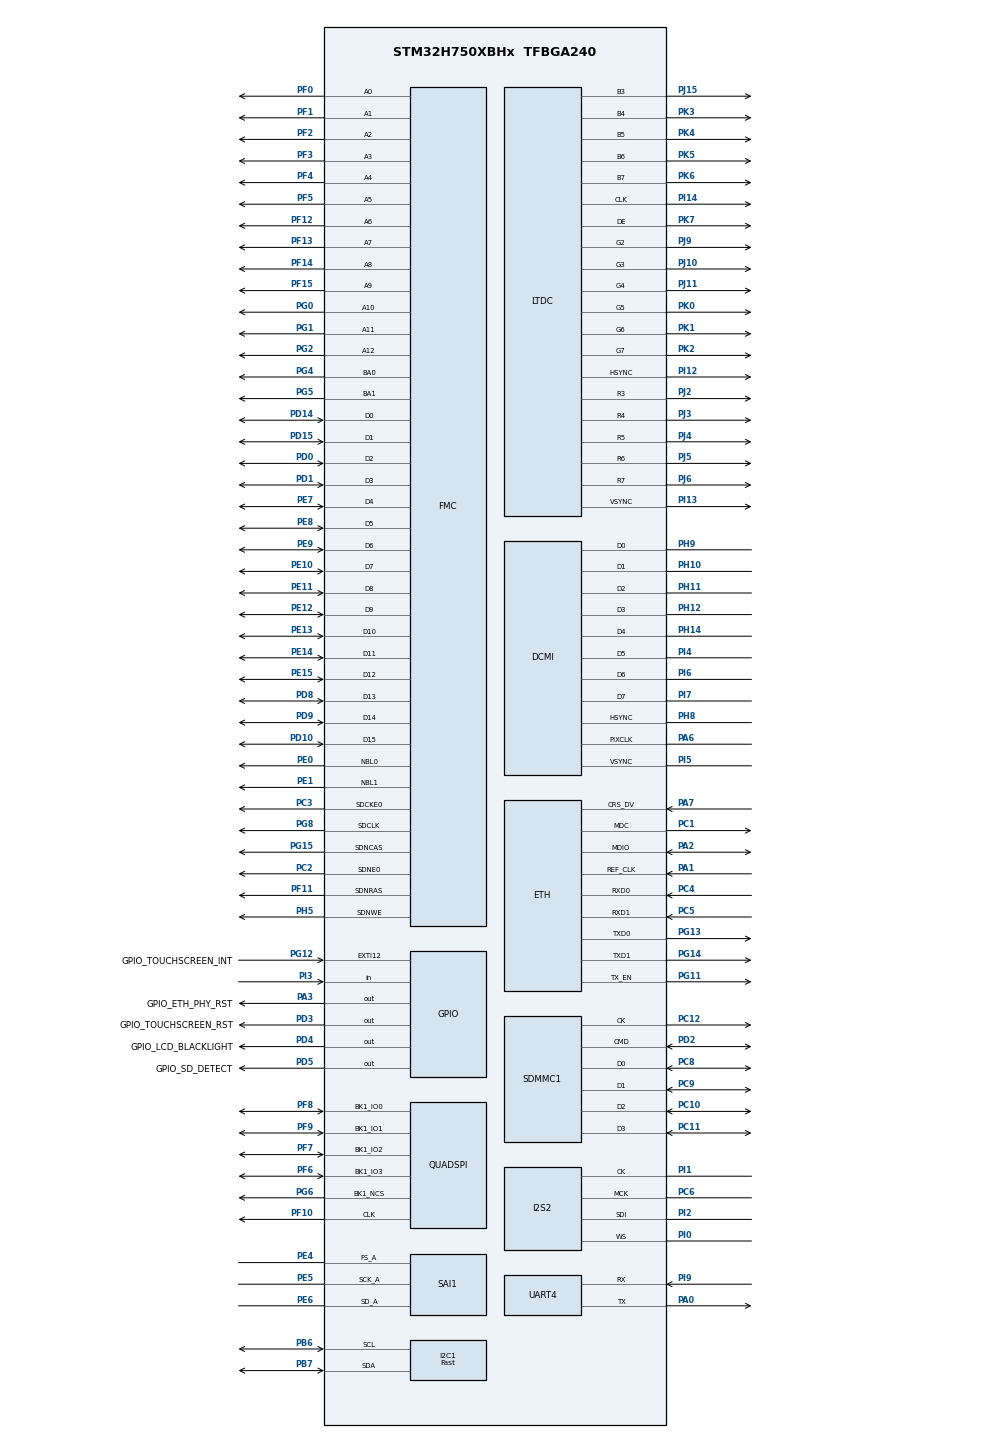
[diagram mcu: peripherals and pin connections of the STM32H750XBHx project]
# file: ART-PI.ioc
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CORTEX_M7.CPU_DCache=Enabled
CORTEX_M7.CPU_ICache=Enabled
CORTEX_M7.Enable_S-Cortex_Memory_Protection_Unit_Region1_Settings_S=__NULL
CORTEX_M7.default_mode_Activation=0
DCMI.JPEGMode=DCMI_JPEG_DISABLE
DMA2D.ColorMode=DMA2D_OUTPUT_RGB565
Dma.I2C1_RX.1.Direction=DMA_PERIPH_TO_MEMORY
Dma.I2C1_RX.1.EventEnable=DISABLE
Dma.I2C1_RX.1.FIFOMode=DMA_FIFOMODE_ENABLE
Dma.I2C1_RX.1.FIFOThreshold=DMA_FIFO_THRESHOLD_FULL
Dma.I2C1_RX.1.Instance=DMA1_Stream1
Dma.I2C1_RX.1.MemBurst=DMA_MBURST_SINGLE
Dma.I2C1_RX.1.MemDataAlignment=DMA_MDATAALIGN_BYTE
Dma.I2C1_RX.1.MemInc=DMA_MINC_ENABLE
Dma.I2C1_RX.1.Mode=DMA_NORMAL
Dma.I2C1_RX.1.PeriphBurst=DMA_PBURST_SINGLE
Dma.I2C1_RX.1.PeriphDataAlignment=DMA_PDATAALIGN_BYTE
Dma.I2C1_RX.1.PeriphInc=DMA_PINC_DISABLE
Dma.I2C1_RX.1.Polarity=HAL_DMAMUX_REQ_GEN_RISING
Dma.I2C1_RX.1.Priority=DMA_PRIORITY_LOW
Dma.I2C1_RX.1.RequestNumber=1
Dma.I2C1_RX.1.SignalID=NONE
Dma.I2C1_RX.1.SyncEnable=DISABLE
Dma.I2C1_RX.1.SyncPolarity=HAL_DMAMUX_SYNC_NO_EVENT
Dma.I2C1_RX.1.SyncRequestNumber=1
Dma.I2C1_RX.1.SyncSignalID=NONE
Dma.I2C1_TX.0.Direction=DMA_MEMORY_TO_PERIPH
Dma.I2C1_TX.0.EventEnable=DISABLE
Dma.I2C1_TX.0.FIFOMode=DMA_FIFOMODE_ENABLE
Dma.I2C1_TX.0.FIFOThreshold=DMA_FIFO_THRESHOLD_FULL
Dma.I2C1_TX.0.Instance=DMA1_Stream0
Dma.I2C1_TX.0.MemBurst=DMA_MBURST_SINGLE
Dma.I2C1_TX.0.MemDataAlignment=DMA_MDATAALIGN_BYTE
Dma.I2C1_TX.0.MemInc=DMA_MINC_ENABLE
Dma.I2C1_TX.0.Mode=DMA_NORMAL
Dma.I2C1_TX.0.PeriphBurst=DMA_PBURST_SINGLE
Dma.I2C1_TX.0.PeriphDataAlignment=DMA_PDATAALIGN_BYTE
Dma.I2C1_TX.0.PeriphInc=DMA_PINC_DISABLE
Dma.I2C1_TX.0.Polarity=HAL_DMAMUX_REQ_GEN_RISING
Dma.I2C1_TX.0.Priority=DMA_PRIORITY_LOW
Dma.I2C1_TX.0.RequestNumber=1
Dma.I2C1_TX.0.SignalID=NONE
Dma.I2C1_TX.0.SyncEnable=DISABLE
Dma.I2C1_TX.0.SyncPolarity=HAL_DMAMUX_SYNC_NO_EVENT
Dma.I2C1_TX.0.SyncRequestNumber=1
Dma.I2C1_TX.0.SyncSignalID=NONE
Dma.Request0=I2C1_TX
Dma.Request1=I2C1_RX
Dma.Request2=SAI1_A
Dma.Request3=SPI2_RX
Dma.SAI1_A.2.Direction=DMA_MEMORY_TO_PERIPH
Dma.SAI1_A.2.EventEnable=DISABLE
Dma.SAI1_A.2.FIFOMode=DMA_FIFOMODE_ENABLE
Dma.SAI1_A.2.FIFOThreshold=DMA_FIFO_THRESHOLD_HALFFULL
Dma.SAI1_A.2.Instance=DMA1_Stream2
Dma.SAI1_A.2.MemBurst=DMA_MBURST_SINGLE
Dma.SAI1_A.2.MemDataAlignment=DMA_MDATAALIGN_HALFWORD
Dma.SAI1_A.2.MemInc=DMA_MINC_ENABLE
Dma.SAI1_A.2.Mode=DMA_CIRCULAR
Dma.SAI1_A.2.PeriphBurst=DMA_PBURST_SINGLE
Dma.SAI1_A.2.PeriphDataAlignment=DMA_PDATAALIGN_HALFWORD
Dma.SAI1_A.2.PeriphInc=DMA_PINC_DISABLE
Dma.SAI1_A.2.Polarity=HAL_DMAMUX_REQ_GEN_RISING
Dma.SAI1_A.2.Priority=DMA_PRIORITY_LOW
Dma.SAI1_A.2.RequestNumber=1
Dma.SAI1_A.2.SignalID=NONE
Dma.SAI1_A.2.SyncEnable=DISABLE
Dma.SAI1_A.2.SyncPolarity=HAL_DMAMUX_SYNC_NO_EVENT
Dma.SAI1_A.2.SyncRequestNumber=1
Dma.SAI1_A.2.SyncSignalID=NONE
Dma.SPI2_RX.3.Direction=DMA_PERIPH_TO_MEMORY
Dma.SPI2_RX.3.EventEnable=DISABLE
Dma.SPI2_RX.3.FIFOMode=DMA_FIFOMODE_ENABLE
Dma.SPI2_RX.3.FIFOThreshold=DMA_FIFO_THRESHOLD_HALFFULL
Dma.SPI2_RX.3.Instance=DMA1_Stream3
Dma.SPI2_RX.3.MemBurst=DMA_MBURST_SINGLE
Dma.SPI2_RX.3.MemDataAlignment=DMA_MDATAALIGN_WORD
Dma.SPI2_RX.3.MemInc=DMA_MINC_ENABLE
Dma.SPI2_RX.3.Mode=DMA_CIRCULAR
Dma.SPI2_RX.3.PeriphBurst=DMA_PBURST_SINGLE
Dma.SPI2_RX.3.PeriphDataAlignment=DMA_PDATAALIGN_WORD
Dma.SPI2_RX.3.PeriphInc=DMA_PINC_DISABLE
Dma.SPI2_RX.3.Polarity=HAL_DMAMUX_REQ_GEN_RISING
Dma.SPI2_RX.3.Priority=DMA_PRIORITY_LOW
Dma.SPI2_RX.3.RequestNumber=1
Dma.SPI2_RX.3.SignalID=NONE
Dma.SPI2_RX.3.SyncEnable=DISABLE
Dma.SPI2_RX.3.SyncPolarity=HAL_DMAMUX_SYNC_NO_EVENT
Dma.SPI2_RX.3.SyncRequestNumber=1
Dma.SPI2_RX.3.SyncSignalID=NONE
ETH.MediaInterface=HAL_ETH_RMII_MODE
FATFS._CODE_PAGE=1
FATFS._FS_LOCK=16
FATFS._LFN_UNICODE=0
FATFS._STRF_ENCODE=0
FATFS._USE_CHMOD=1
FATFS._USE_LFN=0
FATFS._USE_MUTEX=1
FMC.BankMapConfig=FMC_SWAPBMAP_DISABLE
FMC.CASLatency1=FMC_SDRAM_CAS_LATENCY_2
FMC.ColumnBitsNumber1=FMC_SDRAM_COLUMN_BITS_NUM_9
FMC.ExitSelfRefreshDelay1=8
FMC.LoadToActiveDelay1=2
FMC.RCDDelay1=2
FMC.RPDelay1=2
FMC.RPDelay2=2
FMC.ReadBurst1=FMC_SDRAM_RBURST_ENABLE
FMC.ReadBurst2=FMC_SDRAM_RBURST_ENABLE
FMC.RowCycleDelay1=6
FMC.RowCycleDelay2=6
FMC.SDClockPeriod1=FMC_SDRAM_CLOCK_PERIOD_2
FMC.SDClockPeriod2=FMC_SDRAM_CLOCK_PERIOD_2
FMC.SelfRefreshTime1=6
FMC.WriteRecoveryTime1=6
FREERTOS.Tasks01=defaultTask,24,128,StartDefaultTask,Default,NULL,Dynamic,NULL,NULL
FREERTOS.configCHECK_FOR_STACK_OVERFLOW=1
FREERTOS.configENABLE_FPU=1
FREERTOS.configTIMER_TASK_STACK_DEPTH=512
FREERTOS.configTOTAL_HEAP_SIZE=102400
FREERTOS.configUSE_DAEMON_TASK_STARTUP_HOOK=1
FREERTOS.configUSE_IDLE_HOOK=1
FREERTOS.configUSE_MALLOC_FAILED_HOOK=1
FREERTOS.configUSE_NEWLIB_REENTRANT=1
FREERTOS.configUSE_TICK_HOOK=1
I2C1.Analog_Filter=I2C_ANALOGFILTER_DISABLE
I2C1.CustomTiming=Disabled
I2C1.I2C_Coeff_DF=1
I2C1.I2C_Fall_Time=300
I2C1.I2C_Rise_Time=300
I2C1.I2C_Speed_Mode=I2C_Fast
I2C1.Speed=400
I2C1.Timing=0x60640915
I2S2.AudioFreq=I2S_AUDIOFREQ_48K
I2S2.DataFormat=I2S_DATAFORMAT_24B
I2S2.ErrorAudioFreq=-2.34 %
I2S2.Instance=SPI$Index
I2S2.RealAudioFreq=46.875 KHz
LTDC.ActiveH=525
LTDC.ActiveW=840
LTDC.Alpha_L0=255
LTDC.BlendingFactor1_L0=LTDC_BLENDING_FACTOR1_CA
LTDC.FBStartAdress_L0=0xC0000000
LTDC.HBP=40
LTDC.HSync=4
LTDC.ImageHeight_L0=480
LTDC.ImageWidth_L0=800
LTDC.Layers=0
LTDC.PixelFormat_L0=LTDC_PIXEL_FORMAT_RGB565
LTDC.VBP=32
LTDC.VSync=2
LTDC.WindowX1_L0=800
LTDC.WindowX1_L1=800
LTDC.WindowY1_L0=480
LTDC.WindowY1_L1=480
LWIP.BSP.number=1
LWIP.DEFAULT_THREAD_PRIO=5
LWIP.DEFAULT_THREAD_STACKSIZE=2048
LWIP.LWIP_DHCP=1
LWIP.LWIP_DNS=1
LWIP.LWIP_NETCONN=1
LWIP.LWIP_NETIF_EXT_STATUS_CALLBACK=1
LWIP.LWIP_NETIF_LOOPBACK=1
LWIP.LWIP_NETIF_STATUS_CALLBACK=1
LWIP.LWIP_SNMP=0
LWIP.LWIP_SNTP=1
LWIP.TCPIP_THREAD_PRIO=8
LWIP.Version=v2.1.2_Cube
LWIP0.BSP.STBoard=false
LWIP0.BSP.api=BSP_COMPONENT_DRIVER
LWIP0.BSP.component=LAN8742
LWIP0.BSP.instance=LAN8742
LWIP0.BSP.name=Driver_PHY
LWIP0.BSP.semaphore=S_LAN8742
LWIP0.BSP.solution=LAN8742
Mcu.Family=STM32H7
Mcu.Name=STM32H750XBHx
Mcu.Package=TFBGA240
NVIC.DMA1_Stream0_IRQn=true\:5\:0\:false\:false\:true\:true\:false\:true\:true
NVIC.DMA1_Stream1_IRQn=true\:5\:0\:false\:false\:true\:true\:false\:true\:true
NVIC.DMA1_Stream2_IRQn=true\:5\:0\:false\:false\:true\:true\:false\:true\:true
NVIC.DMA1_Stream3_IRQn=true\:5\:0\:false\:false\:true\:true\:false\:true\:true
NVIC.DMA2D_IRQn=true\:5\:0\:false\:false\:true\:true\:true\:true\:true
NVIC.ETH_IRQn=true\:5\:0\:false\:false\:true\:true\:true\:true\:true
NVIC.EXTI15_10_IRQn=true\:5\:0\:false\:false\:true\:true\:true\:true\:true
NVIC.I2C1_EV_IRQn=true\:5\:0\:false\:false\:true\:true\:true\:true\:true
NVIC.LTDC_IRQn=true\:5\:0\:false\:false\:true\:true\:true\:true\:true
NVIC.PriorityGroup=NVIC_PRIORITYGROUP_4
NVIC.SDMMC1_IRQn=true\:5\:0\:false\:false\:true\:true\:true\:true\:true
NVIC.SPI2_IRQn=true\:5\:0\:false\:false\:true\:true\:true\:true\:true
NVIC.TIM4_IRQn=true\:15\:0\:false\:false\:true\:false\:false\:true\:true
NVIC.TimeBase=TIM4_IRQn
NVIC.TimeBaseIP=TIM4
PA0.Mode=Asynchronous
PA0.Signal=UART4_TX
PA1.GPIO_Mode=GPIO_MODE_AF_PP
PA1.GPIO_PuPd=GPIO_PULLUP
PA1.GPIO_Speed=GPIO_SPEED_FREQ_VERY_HIGH
PA1.Mode=RMII
PA1.Signal=ETH_REF_CLK
PA13\ (JTMS/SWDIO).Mode=Serial_Wire
PA13\ (JTMS/SWDIO).Signal=DEBUG_JTMS-SWDIO
PA14\ (JTCK/SWCLK).Mode=Serial_Wire
PA14\ (JTCK/SWCLK).Signal=DEBUG_JTCK-SWCLK
PA2.GPIO_Mode=GPIO_MODE_AF_PP
PA2.GPIO_PuPd=GPIO_PULLUP
PA2.GPIO_Speed=GPIO_SPEED_FREQ_VERY_HIGH
PA2.Mode=RMII
PA2.Signal=ETH_MDIO
PA3.GPIO_Label=GPIO_ETH_PHY_RST
PA3.Signal=GPIO_Output
PA6.GPIO_Mode=GPIO_MODE_AF_PP
PA6.GPIO_PuPd=GPIO_PULLUP
PA6.GPIO_Speed=GPIO_SPEED_FREQ_VERY_HIGH
PA6.Mode=Slave_8_bits_External_Synchro
PA6.Signal=DCMI_PIXCLK
PA7.GPIO_Mode=GPIO_MODE_AF_PP
PA7.GPIO_PuPd=GPIO_PULLUP
PA7.GPIO_Speed=GPIO_SPEED_FREQ_VERY_HIGH
PA7.Mode=RMII
PA7.Signal=ETH_CRS_DV
PB6.GPIO_Pu=GPIO_PULLUP
PB6.GPIO_Speed=GPIO_SPEED_FREQ_VERY_HIGH
PB6.Mode=I2C
PB6.Signal=I2C1_SCL
PB7.GPIO_Pu=GPIO_PULLUP
PB7.GPIO_Speed=GPIO_SPEED_FREQ_VERY_HIGH
PB7.Mode=I2C
PB7.Signal=I2C1_SDA
PC1.GPIO_Mode=GPIO_MODE_AF_PP
PC1.GPIO_PuPd=GPIO_PULLUP
PC1.GPIO_Speed=GPIO_SPEED_FREQ_VERY_HIGH
PC1.Mode=RMII
PC1.Signal=ETH_MDC
PC10.GPIO_Mode=GPIO_MODE_AF_PP
PC10.GPIO_PuPd=GPIO_PULLUP
PC10.GPIO_Speed_High_Default=GPIO_SPEED_FREQ_VERY_HIGH
PC10.Mode=SD_4_bits_Wide_bus
PC10.Signal=SDMMC1_D2
PC11.GPIO_Mode=GPIO_MODE_AF_PP
PC11.GPIO_PuPd=GPIO_PULLUP
PC11.GPIO_Speed_High_Default=GPIO_SPEED_FREQ_VERY_HIGH
PC11.Mode=SD_4_bits_Wide_bus
PC11.Signal=SDMMC1_D3
PC12.GPIO_Mode=GPIO_MODE_AF_PP
PC12.GPIO_PuPd=GPIO_PULLUP
PC12.GPIO_Speed_High_Default=GPIO_SPEED_FREQ_VERY_HIGH
PC12.Mode=SD_4_bits_Wide_bus
PC12.Signal=SDMMC1_CK
PC14-OSC32_IN\ (OSC32_IN).Mode=LSE-External-Oscillator
PC14-OSC32_IN\ (OSC32_IN).Signal=RCC_OSC32_IN
PC15-OSC32_OUT\ (OSC32_OUT).Mode=LSE-External-Oscillator
PC15-OSC32_OUT\ (OSC32_OUT).Signal=RCC_OSC32_OUT
PC2.Mode=SdramChipSelect1_1
PC2.Signal=FMC_SDNE0
PC3.Mode=SdramChipSelect1_1
PC3.Signal=FMC_SDCKE0
PC4.GPIO_Mode=GPIO_MODE_AF_PP
PC4.GPIO_PuPd=GPIO_PULLUP
PC4.GPIO_Speed=GPIO_SPEED_FREQ_VERY_HIGH
PC4.Mode=RMII
PC4.Signal=ETH_RXD0
PC5.GPIO_Mode=GPIO_MODE_AF_PP
PC5.GPIO_PuPd=GPIO_PULLUP
PC5.GPIO_Speed=GPIO_SPEED_FREQ_VERY_HIGH
PC5.Mode=RMII
PC5.Signal=ETH_RXD1
PC6.Mode=Master_Clock_Activated
PC6.Signal=I2S2_MCK
PC8.GPIO_Mode=GPIO_MODE_AF_PP
PC8.GPIO_PuPd=GPIO_PULLUP
PC8.GPIO_Speed_High_Default=GPIO_SPEED_FREQ_VERY_HIGH
PC8.Mode=SD_4_bits_Wide_bus
PC8.Signal=SDMMC1_D0
PC9.GPIO_Mode=GPIO_MODE_AF_PP
PC9.GPIO_PuPd=GPIO_PULLUP
PC9.GPIO_Speed_High_Default=GPIO_SPEED_FREQ_VERY_HIGH
PC9.Mode=SD_4_bits_Wide_bus
PC9.Signal=SDMMC1_D1
PD0.Signal=FMC_D2_DA2
PD1.Signal=FMC_D3_DA3
PD10.Signal=FMC_D15_DA15
PD14.Signal=FMC_D0_DA0
PD15.Signal=FMC_D1_DA1
PD2.GPIO_PuPd=GPIO_PULLUP
PD2.GPIO_Speed_High_Default=GPIO_SPEED_FREQ_VERY_HIGH
PD2.Mode=SD_4_bits_Wide_bus
PD2.Signal=SDMMC1_CMD
PD3.GPIO_Label=GPIO_TOUCHSCREEN_RST
PD3.PinState=GPIO_PIN_RESET
PD3.Signal=GPIO_Output
PD4.GPIO_Label=GPIO_LCD_BLACKLIGHT
PD4.PinState=GPIO_PIN_SET
PD4.Signal=GPIO_Output
PD5.GPIO_Label=GPIO_SD_DETECT
PD5.Signal=GPIO_Output
PD8.Signal=FMC_D13_DA13
PD9.Signal=FMC_D14_DA14
PE0.Signal=FMC_NBL0
PE1.Signal=FMC_NBL1
PE10.Signal=FMC_D7_DA7
PE11.Signal=FMC_D8_DA8
PE12.Signal=FMC_D9_DA9
PE13.Signal=FMC_D10_DA10
PE14.Signal=FMC_D11_DA11
PE15.Signal=FMC_D12_DA12
PE4.Mode=SAI_A_Master
PE4.Signal=SAI1_FS_A
PE5.Mode=SAI_A_Master
PE5.Signal=SAI1_SCK_A
PE6.Mode=SAI_A_Master
PE6.Signal=SAI1_SD_A
PE7.Signal=FMC_D4_DA4
PE8.Signal=FMC_D5_DA5
PE9.Signal=FMC_D6_DA6
PF0.Signal=FMC_A0
PF1.Signal=FMC_A1
PF10.GPIO_Speed=GPIO_SPEED_FREQ_VERY_HIGH
PF10.Mode=Single Bank 1
PF10.Signal=QUADSPI_CLK
PF11.Signal=FMC_SDNRAS
PF12.Signal=FMC_A6
PF13.Signal=FMC_A7
PF14.Signal=FMC_A8
PF15.Signal=FMC_A9
PF2.Signal=FMC_A2
PF3.Signal=FMC_A3
PF4.Signal=FMC_A4
PF5.Signal=FMC_A5
PF6.GPIO_Speed=GPIO_SPEED_FREQ_VERY_HIGH
PF6.Mode=Single Bank 1
PF6.Signal=QUADSPI_BK1_IO3
PF7.GPIO_Speed=GPIO_SPEED_FREQ_VERY_HIGH
PF7.Mode=Single Bank 1
PF7.Signal=QUADSPI_BK1_IO2
PF8.GPIO_Speed=GPIO_SPEED_FREQ_VERY_HIGH
PF8.Mode=Single Bank 1
PF8.Signal=QUADSPI_BK1_IO0
PF9.GPIO_Speed=GPIO_SPEED_FREQ_VERY_HIGH
PF9.Mode=Single Bank 1
PF9.Signal=QUADSPI_BK1_IO1
PG0.Signal=FMC_A10
PG1.Signal=FMC_A11
PG11.GPIO_Mode=GPIO_MODE_AF_PP
PG11.GPIO_PuPd=GPIO_PULLUP
PG11.GPIO_Speed=GPIO_SPEED_FREQ_VERY_HIGH
PG11.Mode=RMII
PG11.Signal=ETH_TX_EN
PG12.GPIO_Label=GPIO_TOUCHSCREEN_INT
PG12.GPIO_PuPd=GPIO_PULLUP
PG12.Signal=GPXTI12
PG13.GPIO_Mode=GPIO_MODE_AF_PP
PG13.GPIO_PuPd=GPIO_PULLUP
PG13.GPIO_Speed=GPIO_SPEED_FREQ_VERY_HIGH
PG13.Mode=RMII
PG13.Signal=ETH_TXD0
PG14.GPIO_Mode=GPIO_MODE_AF_PP
PG14.GPIO_PuPd=GPIO_PULLUP
PG14.GPIO_Speed=GPIO_SPEED_FREQ_VERY_HIGH
PG14.Mode=RMII
PG14.Signal=ETH_TXD1
PG15.Signal=FMC_SDNCAS
PG2.Signal=FMC_A12
PG4.Signal=FMC_A14_BA0
PG5.Signal=FMC_A15_BA1
PG6.GPIO_Speed=GPIO_SPEED_FREQ_VERY_HIGH
PG6.Mode=Single Bank 1
PG6.Signal=QUADSPI_BK1_NCS
PG8.Signal=FMC_SDCLK
PH0-OSC_IN\ (PH0).Mode=HSE-External-Oscillator
PH0-OSC_IN\ (PH0).Signal=RCC_OSC_IN
PH1-OSC_OUT\ (PH1).Mode=HSE-External-Oscillator
PH1-OSC_OUT\ (PH1).Signal=RCC_OSC_OUT
PH10.GPIO_Mode=GPIO_MODE_AF_PP
PH10.GPIO_PuPd=GPIO_PULLUP
PH10.GPIO_Speed=GPIO_SPEED_FREQ_VERY_HIGH
PH10.Mode=Slave_8_bits_External_Synchro
PH10.Signal=DCMI_D1
PH11.GPIO_Mode=GPIO_MODE_AF_PP
PH11.GPIO_PuPd=GPIO_PULLUP
PH11.GPIO_Speed=GPIO_SPEED_FREQ_VERY_HIGH
PH11.Mode=Slave_8_bits_External_Synchro
PH11.Signal=DCMI_D2
PH12.GPIO_Mode=GPIO_MODE_AF_PP
PH12.GPIO_PuPd=GPIO_PULLUP
PH12.GPIO_Speed=GPIO_SPEED_FREQ_VERY_HIGH
PH12.Mode=Slave_8_bits_External_Synchro
PH12.Signal=DCMI_D3
PH14.GPIO_Mode=GPIO_MODE_AF_PP
PH14.GPIO_PuPd=GPIO_PULLUP
PH14.GPIO_Speed=GPIO_SPEED_FREQ_VERY_HIGH
PH14.Mode=Slave_8_bits_External_Synchro
PH14.Signal=DCMI_D4
PH5.Signal=FMC_SDNWE
PH8.GPIO_Mode=GPIO_MODE_AF_PP
PH8.GPIO_PuPd=GPIO_PULLUP
PH8.GPIO_Speed=GPIO_SPEED_FREQ_VERY_HIGH
PH8.Mode=Slave_8_bits_External_Synchro
PH8.Signal=DCMI_HSYNC
PH9.GPIO_Mode=GPIO_MODE_AF_PP
PH9.GPIO_PuPd=GPIO_PULLUP
PH9.GPIO_Speed=GPIO_SPEED_FREQ_VERY_HIGH
PH9.Mode=Slave_8_bits_External_Synchro
PH9.Signal=DCMI_D0
PI0.GPIO_Speed=GPIO_SPEED_FREQ_VERY_HIGH
PI0.Mode=Half_Duplex_Master_Rx
PI0.Signal=I2S2_WS
PI1.GPIO_Speed=GPIO_SPEED_FREQ_VERY_HIGH
PI1.Mode=Half_Duplex_Master_Rx
PI1.Signal=I2S2_CK
PI12.GPIO_Speed=GPIO_SPEED_FREQ_VERY_HIGH
PI12.Mode=RGB565
PI12.Signal=LTDC_HSYNC
PI13.GPIO_Speed=GPIO_SPEED_FREQ_VERY_HIGH
PI13.Mode=RGB565
PI13.Signal=LTDC_VSYNC
PI14.GPIO_Speed=GPIO_SPEED_FREQ_VERY_HIGH
PI14.Mode=RGB565
PI14.Signal=LTDC_CLK
PI2.GPIO_Speed=GPIO_SPEED_FREQ_VERY_HIGH
PI2.Mode=Half_Duplex_Master_Rx
PI2.Signal=I2S2_SDI
PI3.GPIO_PuPd=GPIO_NOPULL
PI3.Signal=GPIO_Input
PI4.GPIO_Mode=GPIO_MODE_AF_PP
PI4.GPIO_PuPd=GPIO_PULLUP
PI4.GPIO_Speed=GPIO_SPEED_FREQ_VERY_HIGH
PI4.Mode=Slave_8_bits_External_Synchro
PI4.PinAttribute=Free
PI4.Signal=DCMI_D5
PI5.GPIO_Mode=GPIO_MODE_AF_PP
PI5.GPIO_PuPd=GPIO_PULLUP
PI5.GPIO_Speed=GPIO_SPEED_FREQ_VERY_HIGH
PI5.Mode=Slave_8_bits_External_Synchro
PI5.PinAttribute=Free
PI5.Signal=DCMI_VSYNC
PI6.GPIO_Mode=GPIO_MODE_AF_PP
PI6.GPIO_PuPd=GPIO_PULLUP
PI6.GPIO_Speed=GPIO_SPEED_FREQ_VERY_HIGH
PI6.Mode=Slave_8_bits_External_Synchro
PI6.PinAttribute=Free
PI6.Signal=DCMI_D6
PI7.GPIO_Mode=GPIO_MODE_AF_PP
PI7.GPIO_PuPd=GPIO_PULLUP
PI7.GPIO_Speed=GPIO_SPEED_FREQ_VERY_HIGH
PI7.Mode=Slave_8_bits_External_Synchro
PI7.Signal=DCMI_D7
PI9.Mode=Asynchronous
PI9.Signal=UART4_RX
PJ0.Signal=LTDC_R1
PJ10.GPIO_Speed=GPIO_SPEED_FREQ_VERY_HIGH
PJ10.Mode=RGB565
PJ10.Signal=LTDC_G3
PJ11.GPIO_Speed=GPIO_SPEED_FREQ_VERY_HIGH
PJ11.Mode=RGB565
PJ11.Signal=LTDC_G4
PJ12.GPIO_Speed=GPIO_SPEED_FREQ_VERY_HIGH
PJ12.Signal=LTDC_B0
PJ13.GPIO_Speed=GPIO_SPEED_FREQ_VERY_HIGH
PJ13.Signal=LTDC_B1
PJ14.GPIO_Speed=GPIO_SPEED_FREQ_VERY_HIGH
PJ14.Signal=LTDC_B2
PJ15.GPIO_Speed=GPIO_SPEED_FREQ_VERY_HIGH
PJ15.Mode=RGB565
PJ15.Signal=LTDC_B3
PJ2.GPIO_Speed=GPIO_SPEED_FREQ_VERY_HIGH
PJ2.Mode=RGB565
PJ2.Signal=LTDC_R3
PJ3.GPIO_Speed=GPIO_SPEED_FREQ_VERY_HIGH
PJ3.Mode=RGB565
PJ3.Signal=LTDC_R4
PJ4.GPIO_Speed=GPIO_SPEED_FREQ_VERY_HIGH
PJ4.Mode=RGB565
PJ4.Signal=LTDC_R5
PJ5.GPIO_Speed=GPIO_SPEED_FREQ_VERY_HIGH
PJ5.Mode=RGB565
PJ5.Signal=LTDC_R6
PJ6.GPIO_Speed=GPIO_SPEED_FREQ_VERY_HIGH
PJ6.Mode=RGB565
PJ6.Signal=LTDC_R7
PJ9.GPIO_Speed=GPIO_SPEED_FREQ_VERY_HIGH
PJ9.Mode=RGB565
PJ9.Signal=LTDC_G2
PK0.GPIO_Speed=GPIO_SPEED_FREQ_VERY_HIGH
PK0.Mode=RGB565
PK0.Signal=LTDC_G5
PK1.GPIO_Speed=GPIO_SPEED_FREQ_VERY_HIGH
PK1.Mode=RGB565
PK1.Signal=LTDC_G6
PK2.GPIO_Speed=GPIO_SPEED_FREQ_VERY_HIGH
PK2.Mode=RGB565
PK2.Signal=LTDC_G7
PK3.GPIO_Speed=GPIO_SPEED_FREQ_VERY_HIGH
PK3.Mode=RGB565
PK3.Signal=LTDC_B4
PK4.GPIO_Speed=GPIO_SPEED_FREQ_VERY_HIGH
PK4.Mode=RGB565
PK4.Signal=LTDC_B5
PK5.GPIO_Speed=GPIO_SPEED_FREQ_VERY_HIGH
PK5.Mode=RGB565
PK5.PinAttribute=Free
PK5.Signal=LTDC_B6
PK6.GPIO_Speed=GPIO_SPEED_FREQ_VERY_HIGH
PK6.Mode=RGB565
PK6.Signal=LTDC_B7
PK7.GPIO_Speed=GPIO_SPEED_FREQ_VERY_HIGH
PK7.Mode=RGB565
PK7.Signal=LTDC_DE
ProjectManager.HeapSize=0x800
ProjectManager.StackSize=0x800
ProjectManager.TargetToolchain=STM32CubeIDE
QUADSPI.ChipSelectHighTime=QSPI_CS_HIGH_TIME_2_CYCLE
QUADSPI.ClockPrescaler=1
QUADSPI.FifoThreshold=32
QUADSPI.FlashSize=8
QUADSPI.SampleShifting=QSPI_SAMPLE_SHIFTING_HALFCYCLE
RCC.ADCFreq_Value=120000000
RCC.APB1Freq_Value=120000000
RCC.APB2Freq_Value=120000000
RCC.APB3Freq_Value=120000000
RCC.APB4Freq_Value=120000000
RCC.CortexFreq_Value=480000000
RCC.D1PPRE=RCC_APB3_DIV2
RCC.D2PPRE1=RCC_APB1_DIV2
RCC.D2PPRE2=RCC_APB2_DIV2
RCC.D3PPRE=RCC_APB4_DIV2
RCC.DIVM1=5
RCC.DIVM2=25
RCC.DIVM3=20
RCC.DIVN1=192
RCC.DIVN2=240
RCC.DIVN3=240
RCC.DIVQ1=4
RCC.DIVR2=1
RCC.DIVR3=8
RCC.FMCCLockSelection=RCC_FMCCLKSOURCE_PLL2
RCC.HCLKFreq_Value=240000000
RCC.HPRE=RCC_HCLK_DIV2
RCC.PLL2FRACN=0
RCC.PLL3FRACN=0
RCC.PLLSourceVirtual=RCC_PLLSOURCE_HSE
RCC.SAI1CLockSelection=RCC_SAI1CLKSOURCE_PLL3
RCC.SPI123CLockSelection=RCC_SPI123CLKSOURCE_PLL2
RCC.SYSCLKFreq_VALUE=480000000
RCC.SYSCLKSource=RCC_SYSCLKSOURCE_PLLCLK
RCC.Tim1Mul=2
RCC.Tim2Mul=2
RCC.USBFreq_Value=240000000
SAI1.AudioFrequency-SAI_A_Master=SAI_AUDIO_FREQUENCY_22K
SAI1.ErrorAudioFreq-SAI_A_Master=2.43 %
SAI1.FIFOThreshold-SAI_A_Master=SAI_FIFOTHRESHOLD_HF
SAI1.InitProtocol-SAI_A_Master=Enable
SAI1.Instance-SAI_A_Master=SAI$Index_Block_A
SAI1.MClockEnable-SAI_A_Master=SAI_MASTERCLOCK_DISABLE
SAI1.NoDivider-SAI_A_Master=SAI_MASTERDIVIDER_ENABLE
SAI1.OutputDrive-SAI_A_Master=SAI_OUTPUTDRIVE_ENABLE
SAI1.RealAudioFreq-SAI_A_Master=22.536 KHz
SAI1.VirtualMode-SAI_A_Master=VM_MASTER
SAI1.VirtualProtocol-SAI_A_BASIC=VM_BASIC_PROTOCOL
SDMMC1.ClockDiv=3
SH.FMC_A0.0=FMC_A0,13b-sda1
SH.FMC_A1.0=FMC_A1,13b-sda1
SH.FMC_A10.0=FMC_A10,13b-sda1
SH.FMC_A11.0=FMC_A11,13b-sda1
SH.FMC_A12.0=FMC_A12,13b-sda1
SH.FMC_A14_BA0.0=FMC_BA0,FourSdramBanks1
SH.FMC_A15_BA1.0=FMC_BA1,FourSdramBanks1
SH.FMC_A2.0=FMC_A2,13b-sda1
SH.FMC_A3.0=FMC_A3,13b-sda1
SH.FMC_A4.0=FMC_A4,13b-sda1
SH.FMC_A5.0=FMC_A5,13b-sda1
SH.FMC_A6.0=FMC_A6,13b-sda1
SH.FMC_A7.0=FMC_A7,13b-sda1
SH.FMC_A8.0=FMC_A8,13b-sda1
SH.FMC_A9.0=FMC_A9,13b-sda1
SH.FMC_D0_DA0.0=FMC_D0,sd-16b-d1
SH.FMC_D10_DA10.0=FMC_D10,sd-16b-d1
SH.FMC_D11_DA11.0=FMC_D11,sd-16b-d1
SH.FMC_D12_DA12.0=FMC_D12,sd-16b-d1
SH.FMC_D13_DA13.0=FMC_D13,sd-16b-d1
SH.FMC_D14_DA14.0=FMC_D14,sd-16b-d1
SH.FMC_D15_DA15.0=FMC_D15,sd-16b-d1
SH.FMC_D1_DA1.0=FMC_D1,sd-16b-d1
SH.FMC_D2_DA2.0=FMC_D2,sd-16b-d1
SH.FMC_D3_DA3.0=FMC_D3,sd-16b-d1
SH.FMC_D4_DA4.0=FMC_D4,sd-16b-d1
SH.FMC_D5_DA5.0=FMC_D5,sd-16b-d1
SH.FMC_D6_DA6.0=FMC_D6,sd-16b-d1
SH.FMC_D7_DA7.0=FMC_D7,sd-16b-d1
SH.FMC_D8_DA8.0=FMC_D8,sd-16b-d1
SH.FMC_D9_DA9.0=FMC_D9,sd-16b-d1
SH.FMC_NBL0.0=FMC_NBL0,Sd2ByteEnable1
SH.FMC_NBL1.0=FMC_NBL1,Sd2ByteEnable1
SH.FMC_SDCLK.0=FMC_SDCLK,13b-sda1
SH.FMC_SDNCAS.0=FMC_SDNCAS,13b-sda1
SH.FMC_SDNRAS.0=FMC_SDNRAS,13b-sda1
SH.FMC_SDNWE.0=FMC_SDNWE,13b-sda1
VP_DMA2D_VS_DMA2D.Mode=DMA2D_Activate
VP_FATFS_VS_SDIO.Mode=SDIO
VP_FREERTOS_VS_CMSIS_V2.Mode=CMSIS_V2
VP_LWIP_VS_Enabled.Mode=Enabled
VP_SAI1_VP_$IpInstance_SAIA_SAI_BASIC.Mode=SAI_A_BASIC
VP_SYS_VS_tim4.Mode=TIM4
board=custom

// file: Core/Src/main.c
/* USER CODE BEGIN Header */
/**
  ******************************************************************************
  * @file           : main.c
  * @brief          : Main program body
  ******************************************************************************
  * @attention
  *
  * Copyright (c) 2023 STMicroelectronics.
  * All rights reserved.
  *
  * This software is licensed under terms that can be found in the LICENSE file
  * in the root directory of this software component.
  * If no LICENSE file comes with this software, it is provided AS-IS.
  *
  ******************************************************************************
  */
/* USER CODE END Header */
#include "main.h"
#include "cmsis_os.h"
#include "dcmi.h"
#include "dma.h"
#include "dma2d.h"
#include "fatfs.h"
#include "i2c.h"
#include "i2s.h"
#include "ltdc.h"
#include "lwip.h"
#include "sai.h"
#include "sdmmc.h"
#include "usart.h"
#include "gpio.h"
#include "fmc.h"

/* USER CODE BEGIN Includes */
#include "../Application/user_main.h"
#include "w25qxx.h"
/* USER CODE END Includes */

void SystemClock_Config(void);
void PeriphCommonClock_Config(void);
void MX_FREERTOS_Init(void);

int main(void)
{
  /* USER CODE BEGIN 1 */
  /* MCU Configuration--------------------------------------------------------*/
  MPU_Config();
  /* USER CODE END 1 */
/* Enable the CPU Cache */

  /* Enable I-Cache---------------------------------------------------------*/
  SCB_EnableICache();

  /* Enable D-Cache---------------------------------------------------------*/
  SCB_EnableDCache();

  /* MCU Configuration--------------------------------------------------------*/

  /* Reset of all peripherals, Initializes the Flash interface and the Systick. */
  HAL_Init();

  /* Configure the system clock */
  SystemClock_Config();

/* Configure the peripherals common clocks */
  PeriphCommonClock_Config();

  /* USER CODE BEGIN SysInit */
  __HAL_RCC_D2SRAM1_CLK_ENABLE();
  __HAL_RCC_D2SRAM2_CLK_ENABLE();
  __HAL_RCC_D2SRAM3_CLK_ENABLE();
  W25QXX_Init();
  W25Q_Memory_Mapped_Enable();
  rodata_copy_to_ram();
  /* USER CODE END SysInit */

  /* Initialize all configured peripherals */
  MX_GPIO_Init();
  MX_DMA_Init();
  MX_SDMMC1_SD_Init();
  MX_FATFS_Init();
  MX_FMC_Init();
  MX_DCMI_Init();
  MX_DMA2D_Init();
  MX_LTDC_Init();
  MX_I2C1_Init();
  MX_UART4_Init();
  MX_SAI1_Init();
  MX_I2S2_Init();
  /* USER CODE BEGIN 2 */
  hardware_reset();
  system_init();
  /* USER CODE END 2 */

  /* Init scheduler */
  osKernelInitialize();

  /* Call init function for freertos objects (in freertos.c) */
  MX_FREERTOS_Init();

  /* Start scheduler */
  osKernelStart();

  /* We should never get here as control is now taken by the scheduler */
  /* Infinite loop */
  while (1)
  {

    /* USER CODE BEGIN 3 */
    osDelay(10);
  }
  /* USER CODE END 3 */
}

void SystemClock_Config(void)
{
  RCC_OscInitTypeDef RCC_OscInitStruct = {0};
  RCC_ClkInitTypeDef RCC_ClkInitStruct = {0};

  /** Supply configuration update enable
  */
  HAL_PWREx_ConfigSupply(PWR_LDO_SUPPLY);

  /** Configure the main internal regulator output voltage
  */
  __HAL_PWR_VOLTAGESCALING_CONFIG(PWR_REGULATOR_VOLTAGE_SCALE1);

  while(!__HAL_PWR_GET_FLAG(PWR_FLAG_VOSRDY)) {}

  __HAL_RCC_SYSCFG_CLK_ENABLE();
  __HAL_PWR_VOLTAGESCALING_CONFIG(PWR_REGULATOR_VOLTAGE_SCALE0);

  while(!__HAL_PWR_GET_FLAG(PWR_FLAG_VOSRDY)) {}

  /** Initializes the RCC Oscillators according to the specified parameters
  * in the RCC_OscInitTypeDef structure.
  */
  RCC_OscInitStruct.OscillatorType = RCC_OSCILLATORTYPE_HSE;
  RCC_OscInitStruct.HSEState = RCC_HSE_ON;
  RCC_OscInitStruct.PLL.PLLState = RCC_PLL_ON;
  RCC_OscInitStruct.PLL.PLLSource = RCC_PLLSOURCE_HSE;
  RCC_OscInitStruct.PLL.PLLM = 5;
  RCC_OscInitStruct.PLL.PLLN = 192;
  RCC_OscInitStruct.PLL.PLLP = 2;
  RCC_OscInitStruct.PLL.PLLQ = 4;
  RCC_OscInitStruct.PLL.PLLR = 2;
  RCC_OscInitStruct.PLL.PLLRGE = RCC_PLL1VCIRANGE_2;
  RCC_OscInitStruct.PLL.PLLVCOSEL = RCC_PLL1VCOWIDE;
  RCC_OscInitStruct.PLL.PLLFRACN = 0;
  if (HAL_RCC_OscConfig(&RCC_OscInitStruct) != HAL_OK)
  {
    Error_Handler();
  }

  /** Initializes the CPU, AHB and APB buses clocks
  */
  RCC_ClkInitStruct.ClockType = RCC_CLOCKTYPE_HCLK|RCC_CLOCKTYPE_SYSCLK
                              |RCC_CLOCKTYPE_PCLK1|RCC_CLOCKTYPE_PCLK2
                              |RCC_CLOCKTYPE_D3PCLK1|RCC_CLOCKTYPE_D1PCLK1;
  RCC_ClkInitStruct.SYSCLKSource = RCC_SYSCLKSOURCE_PLLCLK;
  RCC_ClkInitStruct.SYSCLKDivider = RCC_SYSCLK_DIV1;
  RCC_ClkInitStruct.AHBCLKDivider = RCC_HCLK_DIV2;
  RCC_ClkInitStruct.APB3CLKDivider = RCC_APB3_DIV2;
  RCC_ClkInitStruct.APB1CLKDivider = RCC_APB1_DIV2;
  RCC_ClkInitStruct.APB2CLKDivider = RCC_APB2_DIV2;
  RCC_ClkInitStruct.APB4CLKDivider = RCC_APB4_DIV2;

  if (HAL_RCC_ClockConfig(&RCC_ClkInitStruct, FLASH_LATENCY_4) != HAL_OK)
  {
    Error_Handler();
  }
}

void PeriphCommonClock_Config(void)
{
  RCC_PeriphCLKInitTypeDef PeriphClkInitStruct = {0};

  /** Initializes the peripherals clock
  */
  PeriphClkInitStruct.PeriphClockSelection = RCC_PERIPHCLK_FMC|RCC_PERIPHCLK_SAI1
                              |RCC_PERIPHCLK_SPI2|RCC_PERIPHCLK_LTDC;
  PeriphClkInitStruct.PLL2.PLL2M = 25;
  PeriphClkInitStruct.PLL2.PLL2N = 240;
  PeriphClkInitStruct.PLL2.PLL2P = 2;
  PeriphClkInitStruct.PLL2.PLL2Q = 2;
  PeriphClkInitStruct.PLL2.PLL2R = 1;
  PeriphClkInitStruct.PLL2.PLL2RGE = RCC_PLL2VCIRANGE_0;
  PeriphClkInitStruct.PLL2.PLL2VCOSEL = RCC_PLL2VCOWIDE;
  PeriphClkInitStruct.PLL2.PLL2FRACN = 0;
  PeriphClkInitStruct.PLL3.PLL3M = 20;
  PeriphClkInitStruct.PLL3.PLL3N = 240;
  PeriphClkInitStruct.PLL3.PLL3P = 2;
  PeriphClkInitStruct.PLL3.PLL3Q = 2;
  PeriphClkInitStruct.PLL3.PLL3R = 8;
  PeriphClkInitStruct.PLL3.PLL3RGE = RCC_PLL3VCIRANGE_0;
  PeriphClkInitStruct.PLL3.PLL3VCOSEL = RCC_PLL3VCOWIDE;
  PeriphClkInitStruct.PLL3.PLL3FRACN = 0;
  PeriphClkInitStruct.FmcClockSelection = RCC_FMCCLKSOURCE_PLL2;
  PeriphClkInitStruct.Sai1ClockSelection = RCC_SAI1CLKSOURCE_PLL3;
  PeriphClkInitStruct.Spi123ClockSelection = RCC_SPI123CLKSOURCE_PLL2;
  if (HAL_RCCEx_PeriphCLKConfig(&PeriphClkInitStruct) != HAL_OK)
  {
    Error_Handler();
  }
}

void HAL_TIM_PeriodElapsedCallback(TIM_HandleTypeDef *htim)
{
  if (htim->Instance == TIM4) {
    HAL_IncTick();
  }
}

void Error_Handler(void)
{
  /* USER CODE BEGIN Error_Handler_Debug */
  /* User can add his own implementation to report the HAL error return state */
  __disable_irq();
  while (1)
  {
      PRINTF_LINE("Error Handler ...");
      osDelay(200);
  }
  /* USER CODE END Error_Handler_Debug */
}

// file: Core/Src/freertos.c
/* USER CODE BEGIN Header */
/**
  ******************************************************************************
  * File Name          : freertos.c
  * Description        : Code for freertos applications
  ******************************************************************************
  * @attention
  *
  * Copyright (c) 2023 STMicroelectronics.
  * All rights reserved.
  *
  * This software is licensed under terms that can be found in the LICENSE file
  * in the root directory of this software component.
  * If no LICENSE file comes with this software, it is provided AS-IS.
  *
  ******************************************************************************
  */
/* USER CODE END Header */

#include "FreeRTOS.h"
#include "task.h"
#include "main.h"
#include "cmsis_os.h"

/* USER CODE BEGIN Includes */
#include "../Application/user_main.h"
/* USER CODE END Includes */

/* Definitions for defaultTask */
osThreadId_t defaultTaskHandle;
const osThreadAttr_t defaultTask_attributes = {
  .name = "defaultTask",
  .stack_size = 128 * 4,
  .priority = (osPriority_t) osPriorityNormal,
};

void StartDefaultTask(void *argument);

extern void MX_LWIP_Init(void);
void MX_FREERTOS_Init(void); /* (MISRA C 2004 rule 8.1) */

/* Hook prototypes */
void vApplicationIdleHook(void);
void vApplicationTickHook(void);
void vApplicationStackOverflowHook(xTaskHandle xTask, signed char *pcTaskName);
void vApplicationMallocFailedHook(void);
void vApplicationDaemonTaskStartupHook(void);

/* USER CODE BEGIN 2 */
void vApplicationIdleHook( void )
{
   /* vApplicationIdleHook() will only be called if configUSE_IDLE_HOOK is set
   to 1 in FreeRTOSConfig.h. It will be called on each iteration of the idle
   task. It is essential that code added to this hook function never attempts
   to block in any way (for example, call xQueueReceive() with a block time
   specified, or call vTaskDelay()). If the application makes use of the
   vTaskDelete() API function (as this demo application does) then it is also
   important that vApplicationIdleHook() is permitted to return to its calling
   function, because it is the responsibility of the idle task to clean up
   memory allocated by the kernel to any task that has since been deleted. */
}
/* USER CODE END 2 */

/* USER CODE BEGIN 3 */
void vApplicationTickHook( void )
{
   /* This function will be called by each tick interrupt if
   configUSE_TICK_HOOK is set to 1 in FreeRTOSConfig.h. User code can be
   added here, but the tick hook is called from an interrupt context, so
   code must not attempt to block, and only the interrupt safe FreeRTOS API
   functions can be used (those that end in FromISR()). */
}
/* USER CODE END 3 */

/* USER CODE BEGIN 4 */
void vApplicationStackOverflowHook(xTaskHandle xTask, signed char *pcTaskName)
{
   /* Run time stack overflow checking is performed if
   configCHECK_FOR_STACK_OVERFLOW is defined to 1 or 2. This hook function is
   called if a stack overflow is detected. */
}
/* USER CODE END 4 */

/* USER CODE BEGIN 5 */
void vApplicationMallocFailedHook(void)
{
   /* vApplicationMallocFailedHook() will only be called if
   configUSE_MALLOC_FAILED_HOOK is set to 1 in FreeRTOSConfig.h. It is a hook
   function that will get called if a call to pvPortMalloc() fails.
   pvPortMalloc() is called internally by the kernel whenever a task, queue,
   timer or semaphore is created. It is also called by various parts of the
   demo application. If heap_1.c or heap_2.c are used, then the size of the
   heap available to pvPortMalloc() is defined by configTOTAL_HEAP_SIZE in
   FreeRTOSConfig.h, and the xPortGetFreeHeapSize() API function can be used
   to query the size of free heap space that remains (although it does not
   provide information on how the remaining heap might be fragmented). */
}
/* USER CODE END 5 */

/* USER CODE BEGIN DAEMON_TASK_STARTUP_HOOK */
void vApplicationDaemonTaskStartupHook(void)
{
}
/* USER CODE END DAEMON_TASK_STARTUP_HOOK */

void MX_FREERTOS_Init(void) {

  /* Create the thread(s) */
  /* creation of defaultTask */
  defaultTaskHandle = osThreadNew(StartDefaultTask, NULL, &defaultTask_attributes);

}

void StartDefaultTask(void *argument)
{
  /* init code for LWIP */
  MX_LWIP_Init();
  /* USER CODE BEGIN StartDefaultTask */
  defualt_thread_entry();
  /* Infinite loop */
  for(;;)
  {
    osDelay(10);
  }
  /* USER CODE END StartDefaultTask */
}
